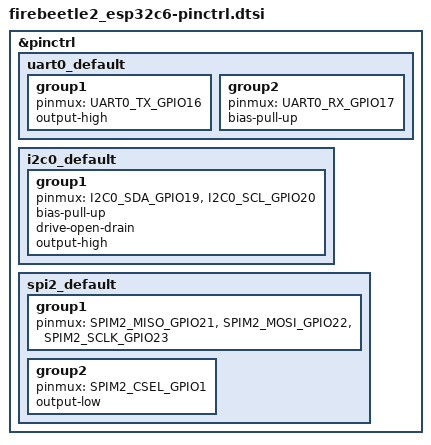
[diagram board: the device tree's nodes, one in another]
/*
 * Copyright (c) 2024 DFRobot
 * SPDX-License-Identifier: Apache-2.0
 */

#include <dt-bindings/pinctrl/esp32c6-pinctrl.h>

&pinctrl {
	uart0_default: uart0_default {
		group1 {
			pinmux = <UART0_TX_GPIO16>;
			output-high;
		};
		group2 {
			pinmux = <UART0_RX_GPIO17>;
			bias-pull-up;
		};
	};

	i2c0_default: i2c0_default {
		group1 {
			pinmux = <I2C0_SDA_GPIO19>,
				 <I2C0_SCL_GPIO20>;
			bias-pull-up;
			drive-open-drain;
			output-high;
		};
	};

	spi2_default: spi2_default {
		group1 {
			pinmux = <SPIM2_MISO_GPIO21>,
				 <SPIM2_MOSI_GPIO22>,
				 <SPIM2_SCLK_GPIO23>;
		};
		group2 {
			pinmux = <SPIM2_CSEL_GPIO1>;
			output-low;
		};
	};
};
